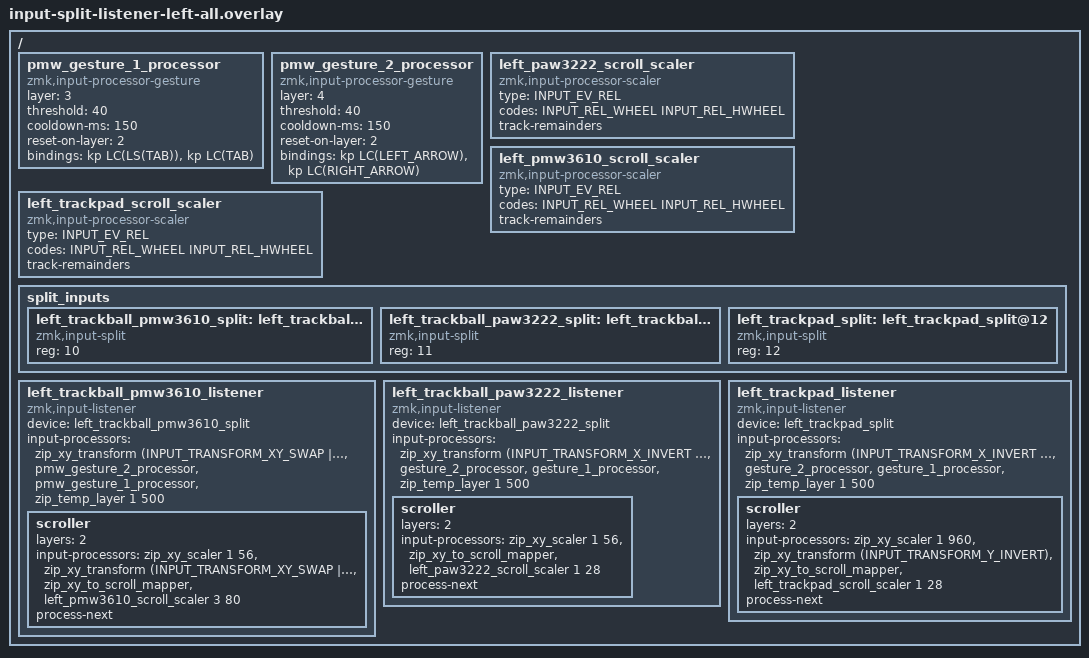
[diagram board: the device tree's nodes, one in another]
#include <dt-bindings/zmk/input_transform.h>

/ {
    /* CPI 800 yields 4/3 as many raw counts as the former CPI 600 setup.
     * Gestures run before pointer scaling, so threshold 40 preserves the
     * original physical travel. PAW3222 and trackpad keep threshold 30. */
    pmw_gesture_1_processor: pmw_gesture_1_processor {
        compatible = "zmk,input-processor-gesture";
        #input-processor-cells = <0>;
        layer = <3>;
        threshold = <40>;
        cooldown-ms = <150>;
        reset-on-layer = <2>;
        bindings = <&kp LC(LS(TAB))>, <&kp LC(TAB)>;
    };

    pmw_gesture_2_processor: pmw_gesture_2_processor {
        compatible = "zmk,input-processor-gesture";
        #input-processor-cells = <0>;
        layer = <4>;
        threshold = <40>;
        cooldown-ms = <150>;
        reset-on-layer = <2>;
        bindings = <&kp LC(LEFT_ARROW)>, <&kp LC(RIGHT_ARROW)>;
    };

    left_paw3222_scroll_scaler: left_paw3222_scroll_scaler {
        compatible = "zmk,input-processor-scaler";
        #input-processor-cells = <2>;
        type = <INPUT_EV_REL>;
        codes = <INPUT_REL_WHEEL INPUT_REL_HWHEEL>;
        track-remainders;
    };

    left_pmw3610_scroll_scaler: left_pmw3610_scroll_scaler {
        compatible = "zmk,input-processor-scaler";
        #input-processor-cells = <2>;
        type = <INPUT_EV_REL>;
        codes = <INPUT_REL_WHEEL INPUT_REL_HWHEEL>;
        track-remainders;
    };

    left_trackpad_scroll_scaler: left_trackpad_scroll_scaler {
        compatible = "zmk,input-processor-scaler";
        #input-processor-cells = <2>;
        type = <INPUT_EV_REL>;
        codes = <INPUT_REL_WHEEL INPUT_REL_HWHEEL>;
        track-remainders;
    };

    split_inputs {
        #address-cells = <1>;
        #size-cells = <0>;

        left_trackball_pmw3610_split: left_trackball_pmw3610_split@10 {
            compatible = "zmk,input-split";
            reg = <10>;
        };

        left_trackball_paw3222_split: left_trackball_paw3222_split@11 {
            compatible = "zmk,input-split";
            reg = <11>;
        };

        left_trackpad_split: left_trackpad_split@12 {
            compatible = "zmk,input-split";
            reg = <12>;
        };
    };

    left_trackball_pmw3610_listener: left_trackball_pmw3610_listener {
        compatible = "zmk,input-listener";
        device = <&left_trackball_pmw3610_split>;
        status = "okay";
        input-processors =
            <&zip_xy_transform (INPUT_TRANSFORM_XY_SWAP | INPUT_TRANSFORM_X_INVERT | INPUT_TRANSFORM_Y_INVERT)>,
            <&pmw_gesture_2_processor>,
            <&pmw_gesture_1_processor>,
            <&zip_temp_layer 1 500>;

        scroller {
            layers = <2>;
            input-processors =
                <&zip_xy_scaler 1 56>,
                <&zip_xy_transform (INPUT_TRANSFORM_XY_SWAP | INPUT_TRANSFORM_X_INVERT)>,
                <&zip_xy_to_scroll_mapper>,
                <&left_pmw3610_scroll_scaler 3 80>;
            process-next;
        };
    };

    left_trackball_paw3222_listener: left_trackball_paw3222_listener {
        compatible = "zmk,input-listener";
        device = <&left_trackball_paw3222_split>;
        status = "okay";
        input-processors =
            <&zip_xy_transform (INPUT_TRANSFORM_X_INVERT | INPUT_TRANSFORM_Y_INVERT)>,
            <&gesture_2_processor>,
            <&gesture_1_processor>,
            <&zip_temp_layer 1 500>;

        scroller {
            layers = <2>;
            input-processors =
                <&zip_xy_scaler 1 56>,
                <&zip_xy_to_scroll_mapper>,
                <&left_paw3222_scroll_scaler 1 28>;
            process-next;
        };
    };

    left_trackpad_listener: left_trackpad_listener {
        compatible = "zmk,input-listener";
        device = <&left_trackpad_split>;
        status = "okay";
        input-processors =
            <&zip_xy_transform (INPUT_TRANSFORM_X_INVERT | INPUT_TRANSFORM_Y_INVERT)>,
            <&gesture_2_processor>,
            <&gesture_1_processor>,
            <&zip_temp_layer 1 500>;

        scroller {
            layers = <2>;
            input-processors =
                <&zip_xy_scaler 1 960>,
                <&zip_xy_transform (INPUT_TRANSFORM_Y_INVERT)>,
                <&zip_xy_to_scroll_mapper>,
                <&left_trackpad_scroll_scaler 1 28>;
            process-next;
        };
    };
};
